# STM32WBA24 register map
File version: 0.2
CPU: CM33 r0p1, little endian, MPU, FPU, 4 interrupt priority bits
Registers are 32-bit, read-write, reset 0x0 unless marked. A register's access mark holds for its fields unless they carry their own. Offsets are from the block's base; [hi:lo] are bit positions; {n}, {i} and the like mark numbered series.

## DBGMCU — DBGMCU address block description
Base 0xE0044000
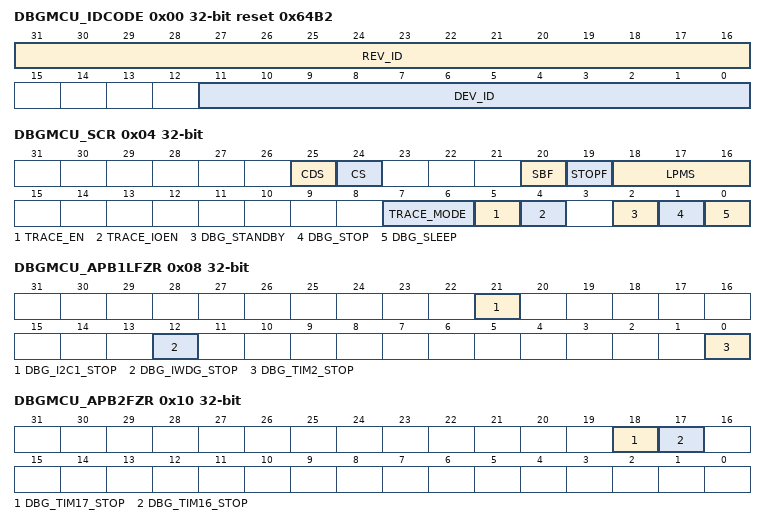
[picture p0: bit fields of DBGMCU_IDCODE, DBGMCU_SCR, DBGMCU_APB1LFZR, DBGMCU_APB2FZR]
0x00 DBGMCU_IDCODE ro reset 0x64B2 (reset mask 0xFFFF) — DBGMCU identity code register
  [31:16] REV_ID — Revision ID
    0x1000=Revision A
  [11:0] DEV_ID — Device ID
    0x4B2=STM32WBA2xxx
0x04 DBGMCU_SCR — DBGMCU status and configuration register
  [25] CDS ro — CPU DeepSleep
    0=CPU not in DeepSleep; 1=CPU in DeepSleep
  [24] CS ro — CPU Sleep
    0=CPU not in Sleep; 1=CPU in Sleep
  [20] SBF ro — Device Standby flag
    0=Device not in Standby mode; 1=Device in Standby mode
  [19] STOPF ro — Device Stop flag
    0=device not in Stop mode; 1=device in Stop mode
  [18:16] LPMS ro — Device low power mode selected
    {v}=Stop {v} mode (v=0..3)
  [7:6] TRACE_MODE — trace pin assigment
    0=trace pins assigned for asynchronous mode (TRACESWO); 1=trace pins assigned for synchronous mode with port width of 1 (TRACECK, TRACED0); 2=trace pins assigned for synchronous mode with port width of 2 (TRACECK, TRACED1:0); 3=trace pins assigned for synchronous mode with port width of 4 (TRACECK, TRACED3:0)
  [5] TRACE_EN — trace port enable
    0=disabled; 1=enabled
  [4] TRACE_IOEN — trace port pins enable
    0=disabled - trace port pins not assigned; 1=enabled - trace port pins assigned according to the selection in TRACE_MODE
  [2] DBG_STANDBY — Allows debug in Standby mode
    0=Normal Standby mode operation, all clocks are disabled automatically in Stop mode and core is powered down; 1=Core power maintained and CPU debug clock enabled in Standby mode, all other are under reset in Stop mode, except for DBGMCU
  [1] DBG_STOP — Allows debug in Stop mode
    0=Normal Stop mode operation, all clocks are disabled automatically in Stop mode; 1=CPU debug clock enabled in Stop mode, all other peripheral clocks are disabled automatically in Stop mode, except for DBGMCU
  [0] DBG_SLEEP — Allows SRAM access in Sleep mode
    0=Normal Sleep mode operation, all clocks are disabled automatically in Sleep mode; 1=SRAM clocks enabled in Sleep mode, all other peripheral clocks are disabled automatically in Sleep mode
0x08 DBGMCU_APB1LFZR — DBGMCU APB1L peripheral freeze register
  [all] fields
    0=Normal operation; 1=Stop in debug
  [21] DBG_I2C1_STOP — I2C1 SMBUS timeout stop in CPU debug
  [12] DBG_IWDG_STOP — IWDG stop in CPU debug
  [0] DBG_TIM2_STOP — TIM2 stop in CPU debug
0x0C DBGMCU_APB1HFZR — DBGMCU APB1H peripheral freeze register
  [5] DBG_LPTIM2_STOP — LPTIM2 stop in CPU debug
    0=Normal operation; 1=Stop in debug
0x10 DBGMCU_APB2FZR — DBGMCU APB2 peripheral freeze register
  [18] DBG_TIM17_STOP — TIM17 stop in CPU debug
    0=Normal operation; 1=Stop in debug
  [17] DBG_TIM16_STOP — TIM16 stop in CPU debug
    0=Normal operation; 1=Stop in debug
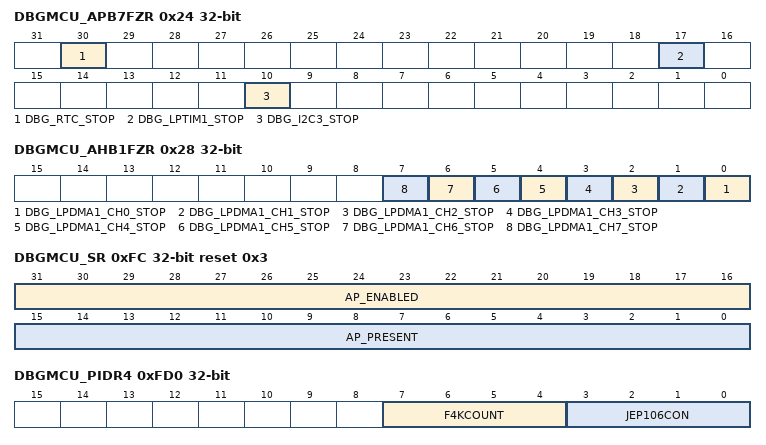
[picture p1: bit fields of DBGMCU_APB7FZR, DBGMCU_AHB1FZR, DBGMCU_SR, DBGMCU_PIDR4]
0x24 DBGMCU_APB7FZR — DBGMCU APB7 peripheral freeze register
  [all] fields
    0=Normal operation; 1=Stop in debug
  [30] DBG_RTC_STOP — RTC stop in CPU debug
  [17] DBG_LPTIM1_STOP — LPTIM1 stop in CPU debug
  [10] DBG_I2C3_STOP — I2C3 SMBUS timeout stop in CPU debug
0x28 DBGMCU_AHB1FZR — DBGMCU AHB1 peripheral freeze register
  [all] fields
    0=Normal operation; 1=Stop in debug
  [n] DBG_LPDMA1_CH{n}_STOP (n=0..7) — LPDMA 1 channel {n} stop in CPU debug
0xFC DBGMCU_SR ro reset 0x3 (reset mask 0xFFF0FFFF) — DBGMCU status register
  [31:16] AP_ENABLED — Bit n identifies whether access port APn is open (can be accessed via the debug port) or locked (debug access to the APn is blocked, except for DBGMCU access)
  [15:0] AP_PRESENT — Bit n identifies whether access port APn is present in device
0x100 DBGMCU_DBG_AUTH_HOST wo reset not defined — DBGMCU debug host authentication register
  [31:0] AUTH_KEY — Device authentication key
0x104 DBGMCU_DBG_AUTH_DEVICE ro reset not defined — DBGMCU debug device authentication register
  [31:0] AUTH_ID — Device authentication key
0x7DC DBGMCU_PNCR ro reset not defined — DBGMCU part number codification register
  [31:0] CODIFICATION — Part number codification
    0x303241=STMicroelectronics STM32WBA20xx part number codification; 0x333241=STMicroelectronics STM32WBA23xx part number codification; 0x343241=STMicroelectronics STM32WBA24xx part number codification; 0x353241=STMicroelectronics STM32WBA25xx part number codification
0xFD0 DBGMCU_PIDR4 ro — DBGMCU CoreSight peripheral identity register 4
  [7:4] F4KCOUNT — Register file size
    0=The register file occupies a single 4-Kbyte region
  [3:0] JEP106CON — JEP106 continuation code
    0=STMicroelectronics JEDEC code
0xFE0 DBGMCU_PIDR0 ro — DBGMCU CoreSight peripheral identity register 0
  [7:0] PARTNUM — Part number bits [7:0]
    0=DBGMCU part number
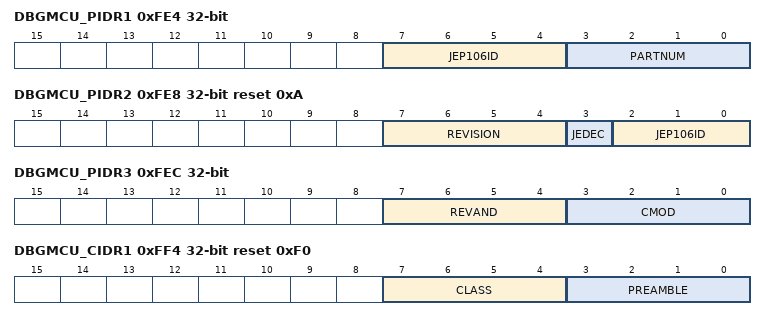
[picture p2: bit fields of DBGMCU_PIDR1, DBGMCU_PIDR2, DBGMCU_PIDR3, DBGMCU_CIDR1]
0xFE4 DBGMCU_PIDR1 ro — DBGMCU CoreSight peripheral identity register 1
  [7:4] JEP106ID — JEP106 identity code bits [3:0]
    0=STMicroelectronics JEDEC code
  [3:0] PARTNUM — Part number bits [11:8]
    0=DBGMCU part number
0xFE8 DBGMCU_PIDR2 ro reset 0xA — DBGMCU CoreSight peripheral identity register 2
  [7:4] REVISION — Component revision number
    0=r0p0
  [3] JEDEC — JEDEC assigned value
    1=Designer identifier specified by JEDEC
  [2:0] JEP106ID — JEP106 identity code bits [6:4]
    2=STMicroelectronics JEDEC code
0xFEC DBGMCU_PIDR3 ro — DBGMCU CoreSight peripheral identity register 3
  [7:4] REVAND — Metal fix version
    0=No metal fix
  [3:0] CMOD — Customer modified
    0=No customer modifications
0xFF0 DBGMCU_CIDR0 ro reset 0xD — DBGMCU CoreSight component identity register 0
  [7:0] PREAMBLE — Component ID bits [7:0]
    13=Common ID value
0xFF4 DBGMCU_CIDR1 ro reset 0xF0 — DBGMCU CoreSight peripheral identity register 1
  [7:4] CLASS — Component ID bits [15:12] - component class
    15=no CoreSight component
  [3:0] PREAMBLE — Component ID bits [11:8]
    0=common ID value
0xFF8 DBGMCU_CIDR2 ro reset 0x5 — DBGMCU CoreSight component identity register 2
  [7:0] PREAMBLE — Component ID bits [23:16]
    5=Common ID value
0xFFC DBGMCU_CIDR3 ro reset 0xB1 — DBGMCU CoreSight component identity register 3
  [7:0] PREAMBLE — Component ID bits [31:24]
    177=Common ID value
